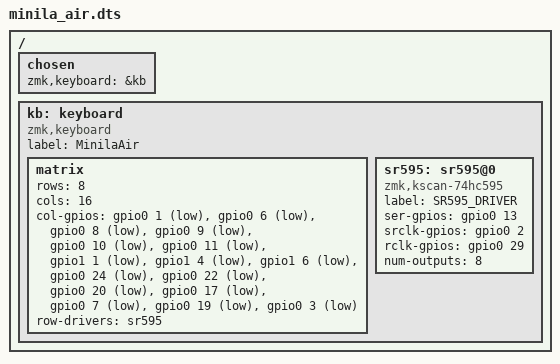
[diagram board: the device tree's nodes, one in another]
/ {
    chosen {
        zmk,keyboard = &kb;
    };

    kb: keyboard {
        compatible = "zmk,keyboard";
        label = "MinilaAir";

        matrix {
            rows = <8>;
            cols = <16>;

            col-gpios = <
                &gpio0 1 GPIO_ACTIVE_LOW
                &gpio0 6 GPIO_ACTIVE_LOW
                &gpio0 8 GPIO_ACTIVE_LOW
                &gpio0 9 GPIO_ACTIVE_LOW
                &gpio0 10 GPIO_ACTIVE_LOW
                &gpio0 11 GPIO_ACTIVE_LOW
                &gpio1 1 GPIO_ACTIVE_LOW
                &gpio1 4 GPIO_ACTIVE_LOW
                &gpio1 6 GPIO_ACTIVE_LOW
                &gpio0 24 GPIO_ACTIVE_LOW
                &gpio0 22 GPIO_ACTIVE_LOW
                &gpio0 20 GPIO_ACTIVE_LOW
                &gpio0 17 GPIO_ACTIVE_LOW
                &gpio0 7 GPIO_ACTIVE_LOW
                &gpio0 19 GPIO_ACTIVE_LOW
                &gpio0 3 GPIO_ACTIVE_LOW
            >;

            row-drivers = <&sr595>;
        };

        sr595: sr595@0 {
            compatible = "zmk,kscan-74hc595";
            label = "SR595_DRIVER";

            ser-gpios = <&gpio0 13 GPIO_ACTIVE_HIGH>;
            srclk-gpios = <&gpio0 2 GPIO_ACTIVE_HIGH>;
            rclk-gpios = <&gpio0 29 GPIO_ACTIVE_HIGH>;
            num-outputs = <8>;
        };
    };
};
